# alb32r003x register map
Vendor: ALB; Series: ALB RT SoC
CPU: ALB XF, little endian
Registers are 32-bit, access not given, reset 0x0 unless marked. A register's access mark holds for its fields unless they carry their own. Offsets are from the block's base; [hi:lo] are bit positions.

## I2C1
Base 0x28002000
Same registers: I2C3 0x26003000, I2C2 0x28003000
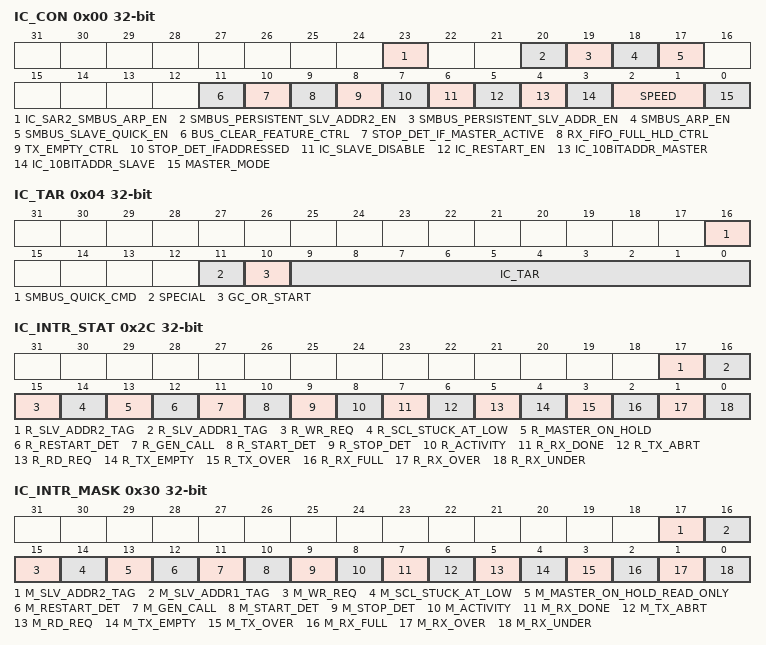
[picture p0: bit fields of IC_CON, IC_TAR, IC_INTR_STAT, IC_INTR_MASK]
0x00 IC_CON
  [23] IC_SAR2_SMBUS_ARP_EN — This bit controls whether DW_apb_i2c should enable Address Resolution Logic in SMBus Mode for IC_SAR2
  [20] SMBUS_PERSISTENT_SLV_ADDR2_EN — The bit controls to enable DW_apb_i2c slave with Slave address 2 (IC_SAR2) as persistent or non persistent
  [19] SMBUS_PERSISTENT_SLV_ADDR_EN — The bit controls to enable DW_apb_i2c slave as persistent or non persistent slave.
  [18] SMBUS_ARP_EN — This bit controls whether DW_apb_i2c should enable Address Resolution Logic in SMBus Mode. The Slave
  [17] SMBUS_SLAVE_QUICK_EN — If this bit is set to 1, DW_apb_i2c slave only receives Quick commands in SMBus Mode.
  [11] BUS_CLEAR_FEATURE_CTRL — This bit controls whether the DW_apb_i2c enables the bus clear feature. For more information, refer to
  [10] STOP_DET_IF_MASTER_ACTIVE — In Master mode:
  [9] RX_FIFO_FULL_HLD_CTRL — This bit controls whether DW_apb_i2c should hold the bus when the Rx FIFO is physically full to its RX_BUFFER_DEPTH,
  [8] TX_EMPTY_CTRL — This bit controls the generation of the TX_EMPTY interrupt, as described in the IC_RAW_INTR_STAT register.
  [7] STOP_DET_IFADDRESSED — In slave mode:
  [6] IC_SLAVE_DISABLE — This bit controls whether I2C has its slave disabled, which means once the presetn signal is applied,
  [5] IC_RESTART_EN — Determines whether RESTART conditions may be sent when acting as a master. Some older slaves do not support
  [4] IC_10BITADDR_MASTER — If the I2C_DYNAMIC_TAR_UPDATE configuration parameter is set to 'No' (0), this bit is named IC_10BITADDR_MASTER
  [3] IC_10BITADDR_SLAVE — When acting as a slave, this bit controls whether the DW_apb_i2c responds to 7- or 10-bit addresses.
  [2:1] SPEED — These bits control at which speed the DW_apb_i2c operates; its setting is relevant only if one is operating
  [0] MASTER_MODE — This bit controls whether the DW_apb_i2c master is enabled.
0x04 IC_TAR
  [16] SMBUS_QUICK_CMD — If bit 11 (SPECIAL) is set to 1, then this bit indicates whether a Quick command is to be performed by
  [11] SPECIAL — This bit indicates whether software performs a Device-ID or General Call or START BYTE command.
  [10] GC_OR_START — If bit 11 (SPECIAL) is set to 1 and bit 13(Device-ID) is set to 0, then this bit indicates whether a
  [9:0] IC_TAR — This is the target address for any master transaction. When transmitting a General Call, these bits are
0x08 IC_SAR
  [9:0] IC_SAR — The IC_SAR holds the slave address when the I2C is operating as a slave. For 7-bit addressing, only IC_SAR[6:0]
0x14 IC_SS_SCL_HCNT
  [15:0] IC_SS_SCL_HCNT — This register must be set before any I2C bus transaction can take place to ensure proper I/O timing.
0x18 IC_SS_SCL_LCNT
  [15:0] IC_SS_SCL_LCNT — This register must be set before any I2C bus transaction can take place to ensure proper I/O timing.
0x1C IC_FS_SCL_HCNT
  [15:0] IC_FS_SCL_HCNT — This register must be set before any I2C bus transaction can take place to ensure proper I/O timing.
0x20 IC_FS_SCL_LCNT
  [15:0] IC_FS_SCL_LCNT — This register must be set before any I2C bus transaction can take place to ensure proper I/O timing.
0x2C IC_INTR_STAT
  [17] R_SLV_ADDR2_TAG — This bit is set to 1 when DW_apb_i2c is acting as slave and another I2C master is attempting to write/read
  [16] R_SLV_ADDR1_TAG — This bit is set to 1 when DW_apb_i2c is acting as slave and another I2C master is attempting to write/read
  [15] R_WR_REQ — This bit is set to 1 when DW_apb_i2c is acting as slave and another I2C master is attempting to werite
  [14] R_SCL_STUCK_AT_LOW — Indicates whether the SCL Line is stuck at low for the IC_SCL_STUCK_LOW_TIMEOUT number of ic_clk periods.
  [13] R_MASTER_ON_HOLD — Indicates whether master is holding the bus and TX FIFO is empty. Enabled only when I2C_DYNAMIC_TAR_UPDATE=1
  [12] R_RESTART_DET — Indicates whether a RESTART condition has occurred on the I2C interface when DW_apb_i2c is operating
  [11] R_GEN_CALL — Set only when a General Call address is received and it is acknowledged. It stays set until it is cleared
  [10] R_START_DET — Indicates whether a START or RESTART condition has occurred on the I2C interface regardless of whether
  [9] R_STOP_DET — Indicates whether a STOP condition has occurred on the I2C interface regardless of whether DW_apb_i2c
  [8] R_ACTIVITY — This bit captures DW_apb_i2c activity and stays set until it is cleared. There are four ways to clear
  [7] R_RX_DONE — When the DW_apb_i2c is acting as a slave-transmitter, this bit is set to 1 if the master does not acknowledge
  [6] R_TX_ABRT — This bit indicates if DW_apb_i2c, as an I2C transmitter, is unable to complete the intended actions on
  [5] R_RD_REQ — This bit is set to 1 when DW_apb_i2c is acting as a slave and another I2C master is attempting to read
  [4] R_TX_EMPTY — The behavior of the TX_EMPTY interrupt status differs based on the TX_EMPTY_CTRL selection in the IC_CON
  [3] R_TX_OVER — Set during transmit if the transmit buffer is filled to IC_TX_BUFFER_DEPTH and the processor attempts
  [2] R_RX_FULL — Set when the receive buffer reaches or goes above the RX_TL threshold in the IC_RX_TL register. It is
  [1] R_RX_OVER — Set if the receive buffer is completely filled to IC_RX_BUFFER_DEPTH and an additional byte is received
  [0] R_RX_UNDER — Set if the processor attempts to read the receive buffer when it is empty by reading from the IC_DATA_CMD
0x30 IC_INTR_MASK
  [17] M_SLV_ADDR2_TAG — This bit masks the R_SLV_ADDR2_TAG interrupt in IC_INTR_STAT register.
  [16] M_SLV_ADDR1_TAG — This bit masks the R_SLV_ADDR1_TAG interrupt in IC_INTR_STAT register.
  [15] M_WR_REQ — This bit masks the R_WR_REQ interrupt in IC_INTR_STAT register.
  [14] M_SCL_STUCK_AT_LOW — This bit masks the R_SCL_STUCK_AT_LOW interrupt in IC_INTR_STAT register.
  [13] M_MASTER_ON_HOLD_READ_ONLY — This M_MASTER_ON_HOLD_read_only bit masks the R_MASTER_ON_HOLD interrupt in IC_INTR_STAT register.
  [12] M_RESTART_DET — This bit masks the R_RESTART_DET interrupt in IC_INTR_STAT register.
  [11] M_GEN_CALL — This bit masks the R_GEN_CALL interrupt in IC_INTR_STAT register.
  [10] M_START_DET — This bit masks the R_START_DET interrupt in IC_INTR_STAT register.
  [9] M_STOP_DET — This bit masks the R_STOP_DET interrupt in IC_INTR_STAT register.
  [8] M_ACTIVITY — This bit masks the R_ACTIVITY interrupt in IC_INTR_STAT register.
  [7] M_RX_DONE — This bit masks the R_RX_DONE interrupt in IC_INTR_STAT register.
  [6] M_TX_ABRT — This bit masks the R_TX_ABRT interrupt in IC_INTR_STAT register.
  [5] M_RD_REQ — This bit masks the R_RD_REQ interrupt in IC_INTR_STAT register.
  [4] M_TX_EMPTY — This bit masks the R_TX_EMPTY interrupt in IC_INTR_STAT register.
  [3] M_TX_OVER — This bit masks the R_TX_OVER interrupt in IC_INTR_STAT register.
  [2] M_RX_FULL — This bit masks the R_RX_FULL interrupt in IC_INTR_STAT register.
  [1] M_RX_OVER — This bit masks the R_RX_OVER interrupt in IC_INTR_STAT register.
  [0] M_RX_UNDER — This bit masks the R_RX_UNDER interrupt in IC_INTR_STAT register.
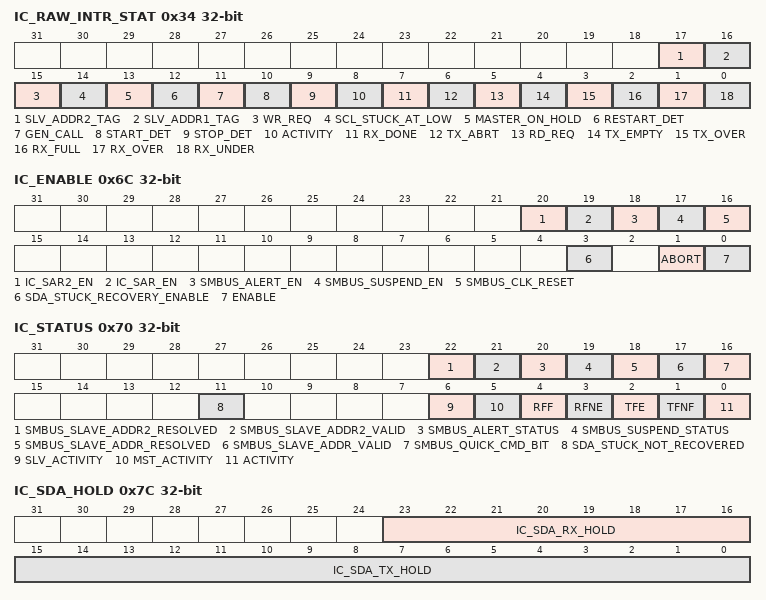
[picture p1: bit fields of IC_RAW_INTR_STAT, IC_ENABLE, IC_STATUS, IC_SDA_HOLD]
0x34 IC_RAW_INTR_STAT
  [17] SLV_ADDR2_TAG — This bit is set to 1 when DW_apb_i2c is acting as slave and another I2C master is attempting to write/read
  [16] SLV_ADDR1_TAG — This bit is set to 1 when DW_apb_i2c is acting as slave and another I2C master is attempting to write/read
  [15] WR_REQ — This bit is set to 1 when DW_apb_i2c is acting as slave and another I2C master is attempting to werite
  [14] SCL_STUCK_AT_LOW — Indicates whether the SCL Line is stuck at low for the IC_SCL_STUCK_LOW_TIMEOUT number of ic_clk periods.
  [13] MASTER_ON_HOLD — Indicates whether master is holding the bus and TX FIFO is empty. Enabled only when I2C_DYNAMIC_TAR_UPDATE=1
  [12] RESTART_DET — Indicates whether a RESTART condition has occurred on the I2C interface when DW_apb_i2c is operating
  [11] GEN_CALL — Set only when a General Call address is received and it is acknowledged. It stays set until it is cleared
  [10] START_DET — Indicates whether a START or RESTART condition has occurred on the I2C interface regardless of whether
  [9] STOP_DET — Indicates whether a STOP condition has occurred on the I2C interface regardless of whether DW_apb_i2c
  [8] ACTIVITY — This bit captures DW_apb_i2c activity and stays set until it is cleared. There are four ways to clear
  [7] RX_DONE — When the DW_apb_i2c is acting as a slave-transmitter, this bit is set to 1 if the master does not acknowledge
  [6] TX_ABRT — This bit indicates if DW_apb_i2c, as an I2C transmitter, is unable to complete the intended actions on
  [5] RD_REQ — This bit is set to 1 when DW_apb_i2c is acting as a slave and another I2C master is attempting to read
  [4] TX_EMPTY — The behavior of the TX_EMPTY interrupt status differs based on the TX_EMPTY_CTRL selection in the IC_CON
  [3] TX_OVER — Set during transmit if the transmit buffer is filled to IC_TX_BUFFER_DEPTH and the processor attempts
  [2] RX_FULL — Set when the receive buffer reaches or goes above the RX_TL threshold in the IC_RX_TL register. It is
  [1] RX_OVER — Set if the receive buffer is completely filled to IC_RX_BUFFER_DEPTH and an additional byte is received
  [0] RX_UNDER — Set if the processor attempts to read the receive buffer when it is empty by reading from the IC_DATA_CMD
0x38 IC_RX_TL
  [0] RX_TL — Receive FIFO Threshold Level.
0x3C IC_TX_TL
  [0] TX_TL — Transmit FIFO Threshold Level.
0x40 IC_CLR_INTR
  [0] CLR_INTR — Read this register to clear the combined interrupt, all individual interrupts, and the IC_TX_ABRT_SOURCE
0x44 IC_CLR_RX_UNDER
  [0] CLR_RX_UNDER — Read this register to clear the RX_UNDER interrupt (bit 0) of the IC_RAW_INTR_STAT register.
0x48 IC_CLR_RX_OVER
  [0] CLR_RX_OVER — Read this register to clear the RX_OVER interrupt (bit 1) of the IC_RAW_INTR_STAT register.
0x4C IC_CLR_TX_OVER
  [0] CLR_TX_OVER — Read this register to clear the TX_OVER interrupt (bit 3) of the IC_RAW_INTR_STAT register.
0x50 IC_CLR_RD_REQ
  [0] CLR_RD_REQ — Read this register to clear the RD_REQ interrupt (bit 5) of the IC_RAW_INTR_STAT register.
0x54 IC_CLR_TX_ABRT
  [0] CLR_TX_ABRT — Read this register to clear the TX_ABRT interrupt (bit 6) of the IC_RAW_INTR_STAT register, and the IC_TX_ABRT_SOURCE
0x58 IC_CLR_RX_DONE
  [0] CLR_RX_DONE — Read this register to clear the RX_DONE interrupt (bit 7) of the IC_RAW_INTR_STAT register.
0x5C IC_CLR_ACTIVITY
  [0] CLR_ACTIVITY — Reading this register clears the ACTIVITY interrupt if the I2C is not active anymore. If the I2C module
0x60 IC_CLR_STOP_DET
  [0] CLR_STOP_DET — Read this register to clear the STOP_DET interrupt (bit 9) of the IC_RAW_INTR_STAT register.
0x64 IC_CLR_START_DET
  [0] CLR_START_DET — Read this register to clear the START_DET interrupt (bit 10) of the IC_RAW_INTR_STAT register.
0x68 IC_CLR_GEN_CALL
  [0] CLR_GEN_CALL — Read this register to clear the GEN_CALL interrupt (bit 11) of IC_RAW_INTR_STAT register.
0x6C IC_ENABLE
  [20] IC_SAR2_EN — Controls whether the DW_apb_i2c SAR2 is enabled.
  [19] IC_SAR_EN — Controls whether the DW_apb_i2c SAR is enabled.
  [18] SMBUS_ALERT_EN — The SMBUS_ALERT_CTRL register bit is used to control assertion of SMBALERT signal.
  [17] SMBUS_SUSPEND_EN — The SMBUS_SUSPEND_EN register bit is used to control assertion and de-assertion of SMBSUS signal.
  [16] SMBUS_CLK_RESET — This bit is used in SMBus Host mode to initiate the SMBus Master Clock Reset. This bit should be enabled
  [3] SDA_STUCK_RECOVERY_ENABLE — If SDA is stuck at low indicated through the TX_ABORT interrupt (IC_TX_ABRT_SOURCE[17]), then this bit
  [1] ABORT — When set, the controller initiates the transfer abort.
  [0] ENABLE — Controls whether the DW_apb_i2c is enabled.
0x70 IC_STATUS
  [22] SMBUS_SLAVE_ADDR2_RESOLVED — This bit indicates whether the slave address 2 (IC_SAR2) is resolved by the ARP Master.
  [21] SMBUS_SLAVE_ADDR2_VALID — This bit indicates whether the slave address 2 (IC_SAR2) is valid or not.
  [20] SMBUS_ALERT_STATUS — This bit indicates the status of the SMBus Alert signal (ic_smbalert_in_n). This signal is asserted when
  [19] SMBUS_SUSPEND_STATUS — This bit indicates the status of the SMBus Suspend signal (ic_smbsus_in_n). This signal is asserted when
  [18] SMBUS_SLAVE_ADDR_RESOLVED — This bit indicates whether the slave address (ic_sar) is resolved by the ARP Master.
  [17] SMBUS_SLAVE_ADDR_VALID — This bit indicates whether the slave address (ic_sar) is valid or not.
  [16] SMBUS_QUICK_CMD_BIT — This bit indicates the R/W bit of the Quick command received. This bit will be cleared after the user
  [11] SDA_STUCK_NOT_RECOVERED — This bit indicates that SDA stuck at low is not recovered after the recovery mechanism. In Slave mode,
  [6] SLV_ACTIVITY — Slave FSM Activity Status. When the Slave Finite State Machine (FSM) is not in the IDLE state, this bit
  [5] MST_ACTIVITY — Master FSM Activity Status. When the Master Finite State Machine (FSM) is not in the IDLE state, this
  [4] RFF — Receive FIFO Completely Full. When the receive FIFO is completely full, this bit is set. When the receive
  [3] RFNE — Receive FIFO Not Empty. This bit is set when the receive FIFO contains one or more entries; it is cleared
  [2] TFE — Transmit FIFO Completely Empty. When the transmit FIFO is completely empty, this bit is set. When it
  [1] TFNF — Transmit FIFO Not Full. Set when the transmit FIFO contains one or more empty locations, and is cleared
  [0] ACTIVITY — I2C Activity Status.
0x74 IC_TXFLR
  [4:0] TXFLR — Transmit FIFO Level. Contains the number of valid data entries in the transmit FIFO.
0x78 IC_RXFLR
  [4:0] RXFLR — Receive FIFO Level. Contains the number of valid data entries in the receive FIFO.
0x7C IC_SDA_HOLD
  [23:16] IC_SDA_RX_HOLD — Sets the required SDA hold time in units of ic_clk period, when DW_apb_i2c acts as a receiver.
  [15:0] IC_SDA_TX_HOLD — Sets the required SDA hold time in units of ic_clk period, when DW_apb_i2c acts as a transmitter.
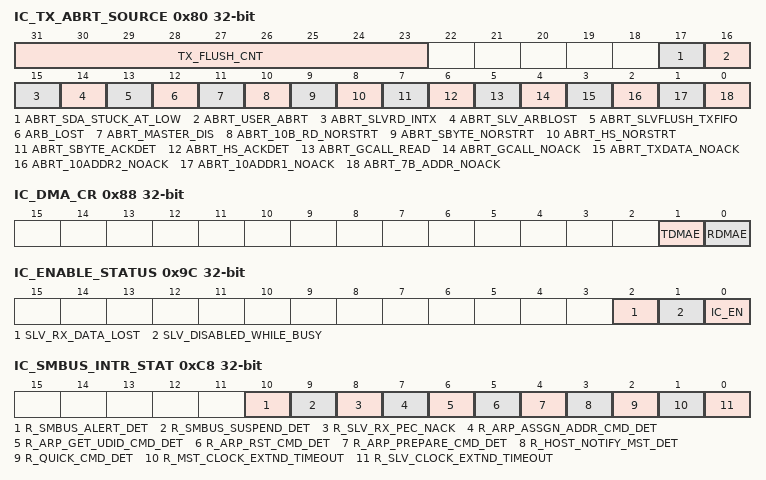
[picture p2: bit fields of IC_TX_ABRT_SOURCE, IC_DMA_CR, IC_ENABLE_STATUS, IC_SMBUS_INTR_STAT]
0x80 IC_TX_ABRT_SOURCE
  [31:23] TX_FLUSH_CNT — This field indicates the number of Tx FIFO Data Commands which are flushed due to TX_ABRT interrupt.
  [17] ABRT_SDA_STUCK_AT_LOW — This is a master-mode-only bit. Master detects the SDA Stuck at low for the IC_SDA_STUCK_AT_LOW_TIMEOUT
  [16] ABRT_USER_ABRT — This is a master-mode-only bit. Master has detected the transfer abort (IC_ENABLE[1])
  [15] ABRT_SLVRD_INTX — When the processor side responds to a slave mode request for data to be transmitted to a remote master
  [14] ABRT_SLV_ARBLOST — This field indicates that a Slave has lost the bus while transmitting data to a remote master. IC_TX_ABRT_SOURCE[12]
  [13] ABRT_SLVFLUSH_TXFIFO — This field specifies that the Slave has received a read command and some data exists in the TX FIFO,
  [12] ARB_LOST — This field specifies that the Master has lost arbitration, or if IC_TX_ABRT_SOURCE[14] is also set, then
  [11] ABRT_MASTER_DIS — This field indicates that the User tries to initiate a Master operation with the Master mode disabled.
  [10] ABRT_10B_RD_NORSTRT — This field indicates that the restart is disabled (IC_RESTART_EN bit (IC_CON[5]) =0) and the master sends
  [9] ABRT_SBYTE_NORSTRT — To clear Bit 9, the source of the ABRT_SBYTE_NORSTRT must be fixed first; restart must be enabled (IC_CON[5]=1),
  [8] ABRT_HS_NORSTRT — This field indicates that the restart is disabled (IC_RESTART_EN bit (IC_CON[5]) =0) and the user is
  [7] ABRT_SBYTE_ACKDET — This field indicates that the Master has sent a START Byte and the START Byte was acknowledged (wrong
  [6] ABRT_HS_ACKDET — This field indicates that the Master is in High Speed mode and the High Speed Master code was acknowledged
  [5] ABRT_GCALL_READ — This field indicates that DW_apb_i2c in the master mode has sent a General Call but the user programmed
  [4] ABRT_GCALL_NOACK — This field indicates that DW_apb_i2c in master mode has sent a General Call and no slave on the bus acknowledged
  [3] ABRT_TXDATA_NOACK — This field indicates the master-mode only bit. When the master receives an acknowledgement for the address,
  [2] ABRT_10ADDR2_NOACK — This field indicates that the Master is in 10-bit address mode and that the second address byte of the
  [1] ABRT_10ADDR1_NOACK — This field indicates that the Master is in 10-bit address mode and the first 10-bit address byte was
  [0] ABRT_7B_ADDR_NOACK — This field indicates that the Master is in 7-bit addressing mode and the address sent was not acknowledged
0x88 IC_DMA_CR
  [1] TDMAE — Transmit DMA Enable. This bit enables/disables the transmit FIFO DMA channel.
  [0] RDMAE — Receive DMA Enable. This bit enables/disables the receive FIFO DMA channel.
0x8C IC_DMA_TDLR
  [3:0] DMATDL — Transmit Data Level. This bit field controls the level at which a DMA request is made by the transmit
0x90 IC_DMA_RDLR
  [3:0] DMARDL — Receive Data Level. This bit field controls the level at which a DMA request is made by the receive logic.
0x94 IC_SDA_SETUP
  [7:0] SDA_SETUP — SDA Setup (tSU:DAT).
0x98 IC_ACK_GENERAL_CALL
  [0] ACK_GEN_CALL — ACK General Call. When set to 1, DW_apb_i2c responds with a ACK (by asserting ic_data_oe) when it receives
0x9C IC_ENABLE_STATUS
  [2] SLV_RX_DATA_LOST — Slave Received Data Lost. This bit indicates if a Slave-Receiver operation has been aborted with at least
  [1] SLV_DISABLED_WHILE_BUSY — Slave Disabled While Busy (Transmit, Receive). This bit indicates if a potential or active Slave operation
  [0] IC_EN — IC Enable Status. This bit always reflects the value driven on the output port ic_en.
0xA0 IC_FS_SPKLEN
  [7:0] IC_FS_SPKLEN — This register must be set before any I2C bus transaction can take place to ensure stable operation. This
0xA8 IC_CLR_RESTART_DET
  [0] CLR_RESTART_DET — Read this register to clear the RESTART_DET interrupt (bit 12) of IC_RAW_INTR_STAT register.
0xAC IC_SCL_STUCK_AT_LOW_TIMEOUT
  [31:0] IC_SCL_STUCK_LOW_TIMEOUT — DW_apb_i2c generate the interrupt to indicate SCL stuck at low (ic_scl_stuck_at_low_intr/ic_scl_stuck_at_low_intr_n)
0xB0 IC_SDA_STUCK_AT_LOW_TIMEOUT
  [31:0] IC_SDA_STUCK_LOW_TIMEOUT — DW_apb_i2c initiates the recovery of SDA line through enabling the SDA_STUCK_RECOVERY_EN (IC_ENABLE[3])
0xB4 IC_CLR_SCL_STUCK_DET
  [0] CLR_SCL_STUCK_DET — Read this register to clear the SCL_STUCT_AT_LOW interrupt (bit 15) of the IC_RAW_INTR_STAT register.
0xBC IC_SMBUS_CLK_LOW_SEXT
  [31:0] SMBUS_CLK_LOW_SEXT_TIMEOUT — This field is used to detect the Slave Clock Extend timeout (tLOW:SEXT) in master mode extended by the
0xC0 IC_SMBUS_CLK_LOW_MEXT
  [31:0] SMBUS_CLK_LOW_MEXT_TIMEOUT — This field is used to detect the Master extend SMBus clock (SCLK) timeout defined from START-to-ACK,
0xC4 IC_SMBUS_THIGH_MAX_IDLE_COUNT
  [15:0] SMBUS_THIGH_MAX_BUS_IDLE_CNT — This field is used to set the required Bus-Idle time period used when a master has been dynamically added
0xC8 IC_SMBUS_INTR_STAT
  [10] R_SMBUS_ALERT_DET — Indicates whether a SMBALERT (ic_smbalert_in_n) signal is driven low by the slave.
  [9] R_SMBUS_SUSPEND_DET — Indicates whether a SMBSUS (ic_smbsus_in_n) signal is driven low by the Host.
  [8] R_SLV_RX_PEC_NACK — Indicates whether a NACK has been sent due to PEC mismatch while working as ARP slave.
  [7] R_ARP_ASSGN_ADDR_CMD_DET — Indicates whether an Assign Address ARP command has been received.
  [6] R_ARP_GET_UDID_CMD_DET — Indicates whether a Get UDID ARP command has been received.
  [5] R_ARP_RST_CMD_DET — Indicates whether a General or Directed Reset ARP command has been received.
  [4] R_ARP_PREPARE_CMD_DET — Indicates whether a prepare to ARP command has been received.
  [3] R_HOST_NOTIFY_MST_DET — Indicates whether a Notify ARP Master ARP command has been received.
  [2] R_QUICK_CMD_DET — Indicates whether a Quick command has been received on the SMBus interface regardless of whether DW_apb_i2c
  [1] R_MST_CLOCK_EXTND_TIMEOUT — Indicates whether the Master device transaction (START-to-ACK, ACK-to-ACK, or ACK-to-STOP) from START
  [0] R_SLV_CLOCK_EXTND_TIMEOUT — Indicates whether the transaction from Slave (i.e from START to STOP) exceeds IC_SMBUS_CLK_LOW_SEXT time.
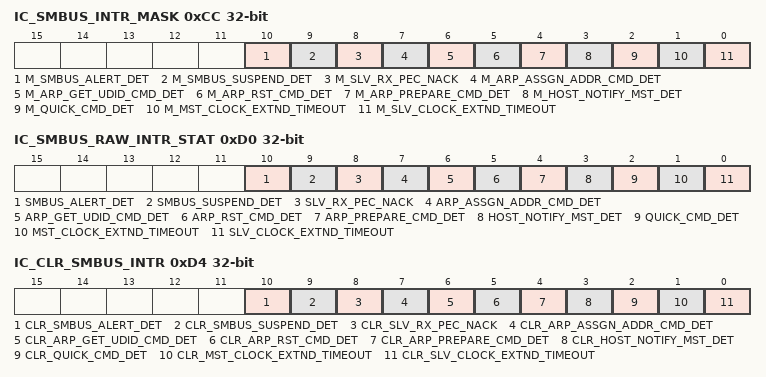
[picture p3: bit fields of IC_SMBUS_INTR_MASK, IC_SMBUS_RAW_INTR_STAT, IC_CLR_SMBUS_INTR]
0xCC IC_SMBUS_INTR_MASK
  [10] M_SMBUS_ALERT_DET — This bit masks the R_SMBUS_ALERT_DET interrupt in IC_SMBUS_INTR_STAT register.
  [9] M_SMBUS_SUSPEND_DET — This bit masks the M_SMBUS_SUSPEND_DET interrupt in IC_SMBUS_INTR_STAT register.
  [8] M_SLV_RX_PEC_NACK — This bit masks the R_SLV_RX_PEC_NACK interrupt in IC_SMBUS_INTR_STAT register.
  [7] M_ARP_ASSGN_ADDR_CMD_DET — This bit masks the R_ARP_ASSGN_ADDR_CMD_DET interrupt in IC_SMBUS_INTR_STAT register.
  [6] M_ARP_GET_UDID_CMD_DET — This bit masks the R_ARP_GET_UDID_CMD_DET interrupt in IC_SMBUS_INTR_STAT register.
  [5] M_ARP_RST_CMD_DET — This bit masks the R_ARP_RST_CMD_DET interrupt in IC_SMBUS_INTR_STAT register.
  [4] M_ARP_PREPARE_CMD_DET — This bit masks the R_ARP_PREPARE_CMD_DET interrupt in IC_SMBUS_INTR_STAT register.
  [3] M_HOST_NOTIFY_MST_DET — This bit masks the R_HOST_NOTIFY_MST_DET interrupt in IC_SMBUS_INTR_STAT register.
  [2] M_QUICK_CMD_DET — This bit masks the R_QUICK_CMD_DET interrupt in IC_SMBUS_INTR_STAT register.
  [1] M_MST_CLOCK_EXTND_TIMEOUT — This bit masks the R_MST_CLOCK_EXTND_TIMEOUT interrupt in IC_SMBUS_INTR_STAT register.
  [0] M_SLV_CLOCK_EXTND_TIMEOUT — This bit masks the R_SLV_CLOCK_EXTND_TIMEOUT interrupt in IC_SMBUS_INTR_STAT register.
0xD0 IC_SMBUS_RAW_INTR_STAT
  [10] SMBUS_ALERT_DET — Indicates whether a SMBALERT (ic_smbalert_in_n) signal is driven low by the slave.
  [9] SMBUS_SUSPEND_DET — Indicates whether a SMBSUS (ic_smbsus_in_n) signal is driven low by the Host.
  [8] SLV_RX_PEC_NACK — Indicates whether a NACK has been sent due to PEC mismatch while working as ARP slave.
  [7] ARP_ASSGN_ADDR_CMD_DET — Indicates whether an Assign Address ARP command has been received.
  [6] ARP_GET_UDID_CMD_DET — Indicates whether a Get UDID ARP command has been received.
  [5] ARP_RST_CMD_DET — Indicates whether a General or Directed Reset ARP command has been received.
  [4] ARP_PREPARE_CMD_DET — Indicates whether a prepare to ARP command has been received.
  [3] HOST_NOTIFY_MST_DET — Indicates whether a Notify ARP Master ARP command has been received.
  [2] QUICK_CMD_DET — Indicates whether a Quick command has been received on the SMBus interface regardless of whether DW_apb_i2c
  [1] MST_CLOCK_EXTND_TIMEOUT — Indicates whether the Master device transaction (START-to-ACK, ACK-to-ACK, or ACK-to-STOP) from START
  [0] SLV_CLOCK_EXTND_TIMEOUT — Indicates whether the transaction from Slave (i.e from START to STOP) exceeds IC_SMBUS_CLK_LOW_SEXT time.
0xD4 IC_CLR_SMBUS_INTR
  [10] CLR_SMBUS_ALERT_DET — Write this register bit to clear the SMBUS_ALERT_DET interrupt (bit 10) of the IC_SMBUS_RAW_INTR_STAT
  [9] CLR_SMBUS_SUSPEND_DET — Write this register bit to clear the SMBUS_SUSPEND_DET interrupt (bit 9) of the IC_SMBUS_RAW_INTR_STAT
  [8] CLR_SLV_RX_PEC_NACK — Write this register bit to clear the SLV_RX_PEC_NACK interrupt (bit 8) of the IC_SMBUS_RAW_INTR_STAT
  [7] CLR_ARP_ASSGN_ADDR_CMD_DET — Write this register bit to clear the ARP_ASSGN_ADDR_CMD_DET interrupt (bit 7) of the IC_SMBUS_RAW_INTR_STAT
  [6] CLR_ARP_GET_UDID_CMD_DET — Write this register bit to clear the ARP_GET_UDID_CMD_DET interrupt (bit 6) of the IC_SMBUS_RAW_INTR_STAT
  [5] CLR_ARP_RST_CMD_DET — Write this register bit to clear the ARP_RST_CMD_DET interrupt (bit 5) of the IC_SMBUS_RAW_INTR_STAT
  [4] CLR_ARP_PREPARE_CMD_DET — Write this register bit to clear the ARP_PREPARE_CMD_DET interrupt (bit 4) of the IC_SMBUS_RAW_INTR_STAT
  [3] CLR_HOST_NOTIFY_MST_DET — Write this register bit to clear the HOST_NOTIFY_MST_DET interrupt (bit 3) of the IC_SMBUS_RAW_INTR_STAT
  [2] CLR_QUICK_CMD_DET — Write this register bit to clear the QUICK_CMD_DET interrupt (bit 2) of the IC_SMBUS_RAW_INTR_STAT register.
  [1] CLR_MST_CLOCK_EXTND_TIMEOUT — Write this register bit to clear the MST_CLOCK_EXTND_TIMEOUT interrupt (bit 1) of the IC_SMBUS_RAW_INTR_STAT
  [0] CLR_SLV_CLOCK_EXTND_TIMEOUT — Write this register bit to clear the SLV_CLOCK_EXTND_TIMEOUT interrupt (bit 0) of the IC_SMBUS_RAW_INTR_STAT
0xDC IC_SMBUS_UDID_LSB
  [31:0] SMBUS_UDID_LSB — This field is used to store the LSB 32 bit value of slave unique device identifier used in Address Resolution
0x100 IC_SAR2
  [9:0] IC_SAR2 — The IC_SAR2 holds the slave address 2 when the I2C is operating as a slave. For 7-bit addressing, only
0x11C IC_CLR_WR_REQ
  [0] CLR_WR_REQ — Read this register to clear the WR_REQ interrupt (bit 15) of the IC_RAW_INTR_STAT register.
0x120 IC_CLR_SLV_ADDR_TAG
  [0] CLR_SLV_ADDR_TAG — Read this register to clear all SLV_ADDRx_TAG (Where x is 1 through IC_NUM_SARS) interrupts (bit 16 ...(16+IC_NUM_SARS-1))
